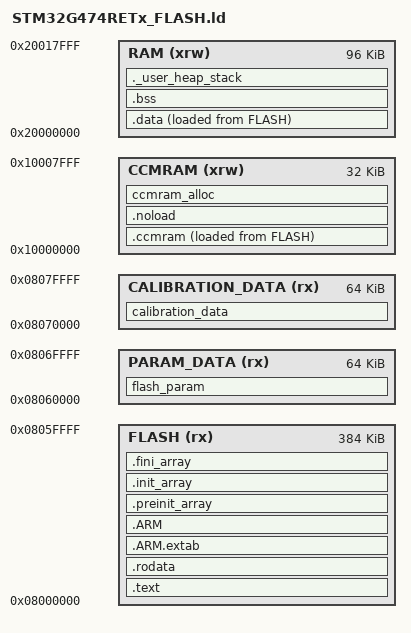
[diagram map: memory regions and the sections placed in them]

/* Entry Point */
ENTRY(Reset_Handler)

/* Highest address of the user mode stack */
_estack = 0x20018000;    /* end of RAM */
/* Generate a link error if heap and stack don't fit into RAM */
_Min_Heap_Size = 32 * 1024;   /* required amount of heap  */
_Min_Stack_Size = 0x2000; /* required amount of stack */

/* Specify the memory areas */
MEMORY
{
RAM (xrw)      : ORIGIN = 0x20000000, LENGTH = 96K
CCMRAM (xrw)   : ORIGIN = 0x10000000, LENGTH = 32K
FLASH (rx)      : ORIGIN = 0x8000000, LENGTH = 384K
PARAM_DATA (rx)  : ORIGIN = 0x8060000, LENGTH = 64K
CALIBRATION_DATA (rx) : ORIGIN = 0x8070000, LENGTH = 64K
}

/* Define output sections */
SECTIONS
{
  /* special param */
  flash_param :
  {
    . = ALIGN(4);
    KEEP(*(flash_param))         /* .rodata sections (constants, strings, etc.) */
    . = ALIGN(4);
  } >PARAM_DATA

  calibration_data :
  {
      . = ALIGN(4);
      KEEP(*(calibration_data)) 
      . = ALIGN(4);
  } >CALIBRATION_DATA

  _siccmram = LOADADDR(.ccmram);
  .ccmram :
  {
    . = ALIGN(4);
    _sccmram = .;
    KEEP(*(.isr_vector)) /* Startup code */
    . = ALIGN(512);
    KEEP(*(flash_start)) /* Address 0x8000200 */
    . = ALIGN(4);
    /* use example : 
      const char obot_hash[41] __attribute__((section("flash_start"),used)) 
        = OBOT_HASH; */
    *(.ccmram)
    *(.ccmram*)
    *memcpy.o(.text)
    KEEP(*flash.o(.text*))
    . = ALIGN(4);
    _eccmram = .;
  } >CCMRAM AT> FLASH

  /* The program code and other data goes into FLASH */
  .text :
  {
    . = ALIGN(4);
    *(.text.Reset_Handler)    /* reset handler early to help if later program corrupted */
    *(.text)           /* .text sections (code) */
    *(.text*)          /* .text* sections (code) */
    *(.glue_7)         /* glue arm to thumb code */
    *(.glue_7t)        /* glue thumb to arm code */
    *(.eh_frame)

    KEEP (*(.init))
    KEEP (*(.fini))

    . = ALIGN(4);
    _etext = .;        /* define a global symbols at end of code */
  } >FLASH


  /* Constant data goes into FLASH */
  .rodata :
  {
    . = ALIGN(4);
    *(.rodata)         /* .rodata sections (constants, strings, etc.) */
    *(.rodata*)        /* .rodata* sections (constants, strings, etc.) */
    . = ALIGN(4);
  } >FLASH

  .ARM.extab   : { *(.ARM.extab* .gnu.linkonce.armextab.*) } >FLASH
  .ARM : {
    __exidx_start = .;
    *(.ARM.exidx*)
    __exidx_end = .;
  } >FLASH

  .preinit_array (READONLY) :
  {
    PROVIDE_HIDDEN (__preinit_array_start = .);
    KEEP (*(.preinit_array*))
    PROVIDE_HIDDEN (__preinit_array_end = .);
  } >FLASH
  .init_array (READONLY) :
  {
    PROVIDE_HIDDEN (__init_array_start = .);
    KEEP (*(SORT(.init_array.*)))
    KEEP (*(.init_array*))
    PROVIDE_HIDDEN (__init_array_end = .);
  } >FLASH
  .fini_array (READONLY) :
  {
    PROVIDE_HIDDEN (__fini_array_start = .);
    KEEP (*(SORT(.fini_array.*)))
    KEEP (*(.fini_array*))
    PROVIDE_HIDDEN (__fini_array_end = .);
  } >FLASH

  .noload (NOLOAD):
  {
    *(.noload)
  } >CCMRAM

  /* Ensure scratch space in ccmram for a cal section copy */
  ccmram_alloc (NOLOAD):
  {
    . += SIZEOF(calibration_data);
  } >CCMRAM


  /* used by the startup to initialize data */
  _sidata = LOADADDR(.data);

  /* Initialized data sections goes into RAM, load LMA copy after code */
  .data : 
  {
    . = ALIGN(4);
    _sdata = .;        /* create a global symbol at data start */
    *(.data)           /* .data sections */
    *(.data*)          /* .data* sections */

    . = ALIGN(4);
    _edata = .;        /* define a global symbol at data end */
  } >RAM AT> FLASH

  
  /* Uninitialized data section */
  . = ALIGN(4);
  .bss :
  {
    /* This is used by the startup in order to initialize the .bss secion */
    _sbss = .;         /* define a global symbol at bss start */
    __bss_start__ = _sbss;
    *(.bss)
    *(.bss*)
    *(COMMON)

    . = ALIGN(4);
    _ebss = .;         /* define a global symbol at bss end */
    __bss_end__ = _ebss;
  } >RAM

  /* User_heap_stack section, used to check that there is enough RAM left */
  ._user_heap_stack :
  {
    . = ALIGN(8);
    PROVIDE ( end = . );
    PROVIDE ( _end = . );
    . = . + _Min_Heap_Size;
    . = . + _Min_Stack_Size;
    . = ALIGN(8);
  } >RAM

  

  /* Remove information from the standard libraries */
  /DISCARD/ :
  {
    libc.a ( * )
    libm.a ( * )
    libgcc.a ( * )
  }

  .ARM.attributes 0 : { *(.ARM.attributes) }
}


